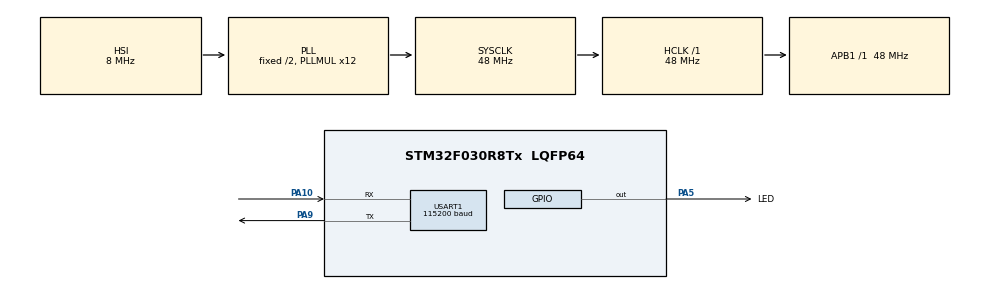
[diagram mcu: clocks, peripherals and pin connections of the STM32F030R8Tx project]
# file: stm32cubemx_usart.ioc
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Mcu.Family=STM32F0
Mcu.Name=STM32F030R8Tx
Mcu.Package=LQFP64
NVIC.USART1_IRQn=true\:0\:0\:false\:false\:true\:true\:true
PA10.GPIO_PuPd=GPIO_NOPULL
PA10.Mode=Asynchronous
PA10.Signal=USART1_RX
PA5.GPIO_Label=LED
PA5.Signal=GPIO_Output
PA9.GPIO_PuPd=GPIO_NOPULL
PA9.Mode=Asynchronous
PA9.Signal=USART1_TX
ProjectManager.HeapSize=0x200
ProjectManager.StackSize=0x400
ProjectManager.TargetToolchain=MDK-ARM V5.27
RCC.AHBFreq_Value=48000000
RCC.APB1Freq_Value=48000000
RCC.APB1TimFreq_Value=48000000
RCC.HCLKFreq_Value=48000000
RCC.PLLMUL=RCC_PLL_MUL12
RCC.SYSCLKFreq_VALUE=48000000
RCC.SYSCLKSource=RCC_SYSCLKSOURCE_PLLCLK
USART1.BaudRate=115200
USART1.VirtualMode-Asynchronous=VM_ASYNC
board=custom

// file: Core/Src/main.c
/* USER CODE BEGIN Header */
/**
  ******************************************************************************
  * @file           : main.c
  * @brief          : Main program body
  ******************************************************************************
  * @attention
  *
  * <h2><center>&copy; Copyright (c) 2020 STMicroelectronics.
  * All rights reserved.</center></h2>
  *
  * This software component is licensed by ST under BSD 3-Clause license,
  * the "License"; You may not use this file except in compliance with the
  * License. You may obtain a copy of the License at:
  *                        opensource.org/licenses/BSD-3-Clause
  *
  ******************************************************************************
  */
/* USER CODE END Header */
#include "main.h"
#include "usart.h"
#include "gpio.h"

/* USER CODE BEGIN Includes */
#include "stdio.h"
/* USER CODE END Includes */

/* USER CODE BEGIN PV */
#define BUFFERSIZE 255           //可以接收的最大字符个数
uint8_t ReceiveBuff[BUFFERSIZE]; //接收缓冲区
uint8_t recv_end_flag = 0,Rx_len;//接收完成中断标志，接收到字符长度

uint8_t RxBuff[1];      //进入中断接收数据的数组
uint8_t DataBuff[5000]; //保存接收到的数据的数组
int RxLine=0;           //接收到的数据长度
/* USER CODE END PV */

void SystemClock_Config(void);
/* USER CODE BEGIN PFP */

//void uart1_data(void);					//接收函数
#ifdef __GNUC__
  #define PUTCHAR_PROTOTYPE int __io_putchar(int ch)
#else
  #define PUTCHAR_PROTOTYPE int fputc(int ch, FILE *f)
#endif

PUTCHAR_PROTOTYPE
{

  // HAL_UART_Transmit_DMA(&huart1, (uint8_t *)&ch,1);
   HAL_UART_Transmit(&huart1, (uint8_t *)(&(ch)), 1, 0xFFFF);
  return ch;
}
/* USER CODE END PFP */

/* USER CODE BEGIN 0 */
//int fputc(int c, FILE *stream)    //重写fputc函数
//{
// /*
//    huart1是工具生成代码定义的UART1结构体，
//    如果以后要使用其他串口打印，只需要把这个结构体改成其他UART结构体。
//*/
//    HAL_UART_Transmit(&huart1, (unsigned char *)&c, 1, 1000);
//    return 1;
//}
//int fputc(int ch, FILE* file)
//{
//    return HAL_UART_Transmit(&huart1, (uint8_t*)&ch, 1, 100);
//}
/* USER CODE END 0 */

int main(void)
{

  /* MCU Configuration--------------------------------------------------------*/

  /* Reset of all peripherals, Initializes the Flash interface and the Systick. */
  HAL_Init();

  /* Configure the system clock */
  SystemClock_Config();

  /* Initialize all configured peripherals */
  MX_GPIO_Init();
  MX_USART1_UART_Init();
  /* USER CODE BEGIN 2 */
	printf("\n111111 \r\n");
//	HAL_UART_Receive_IT(&huart1, (uint8_t *)RxBuff, 1); //打开串口中断接收
//__HAL_UART_ENABLE_IT(&huart1, UART_IT_IDLE);//使能串口1 IDLE中断
  /* USER CODE END 2 */

  /* Infinite loop */
  while (1)
  {

    /* USER CODE BEGIN 3 */

//		printf("\n111111");
		HAL_Delay(1000);
		HAL_GPIO_TogglePin(GPIOA,GPIO_PIN_5);
//		uart1_data();//串口数据处理
  }
  /* USER CODE END 3 */
}

void SystemClock_Config(void)
{
  RCC_OscInitTypeDef RCC_OscInitStruct = {0};
  RCC_ClkInitTypeDef RCC_ClkInitStruct = {0};
  RCC_PeriphCLKInitTypeDef PeriphClkInit = {0};

  /** Initializes the RCC Oscillators according to the specified parameters
  * in the RCC_OscInitTypeDef structure.
  */
  RCC_OscInitStruct.OscillatorType = RCC_OSCILLATORTYPE_HSI;
  RCC_OscInitStruct.HSIState = RCC_HSI_ON;
  RCC_OscInitStruct.HSICalibrationValue = RCC_HSICALIBRATION_DEFAULT;
  RCC_OscInitStruct.PLL.PLLState = RCC_PLL_ON;
  RCC_OscInitStruct.PLL.PLLSource = RCC_PLLSOURCE_HSI;
  RCC_OscInitStruct.PLL.PLLMUL = RCC_PLL_MUL12;
  RCC_OscInitStruct.PLL.PREDIV = RCC_PREDIV_DIV1;
  if (HAL_RCC_OscConfig(&RCC_OscInitStruct) != HAL_OK)
  {
    Error_Handler();
  }
  /** Initializes the CPU, AHB and APB buses clocks
  */
  RCC_ClkInitStruct.ClockType = RCC_CLOCKTYPE_HCLK|RCC_CLOCKTYPE_SYSCLK
                              |RCC_CLOCKTYPE_PCLK1;
  RCC_ClkInitStruct.SYSCLKSource = RCC_SYSCLKSOURCE_PLLCLK;
  RCC_ClkInitStruct.AHBCLKDivider = RCC_SYSCLK_DIV1;
  RCC_ClkInitStruct.APB1CLKDivider = RCC_HCLK_DIV1;

  if (HAL_RCC_ClockConfig(&RCC_ClkInitStruct, FLASH_LATENCY_1) != HAL_OK)
  {
    Error_Handler();
  }
  PeriphClkInit.PeriphClockSelection = RCC_PERIPHCLK_USART1;
  PeriphClkInit.Usart1ClockSelection = RCC_USART1CLKSOURCE_PCLK1;
  if (HAL_RCCEx_PeriphCLKConfig(&PeriphClkInit) != HAL_OK)
  {
    Error_Handler();
  }
}

/* USER CODE BEGIN 4 */
//void uart1_data(void)
//{
//	if(recv_end_flag ==1)//接收完成标志
//	{
//		printf("数据长度=%d\r\n",Rx_len);//打印接收到的数据长度
//		printf("数据内容:");
//		for(int i=0;i<Rx_len;i++)
//		{
//			printf("%c",ReceiveBuff[i]);//向串口打印接收到的数据
//            }
//    printf("\r\n");
//    for(int i = 0; i < Rx_len ; i++) //清空接收缓存区
//    ReceiveBuff[i]=0;//置0
//    Rx_len=0;//接收数据长度清零
//    recv_end_flag=0;//接收标志位清零
//    }
//    //开启下一次接收
//    HAL_UART_Receive_DMA(&huart1,(uint8_t*)ReceiveBuff,BUFFERSIZE);
//}
/* USER CODE END 4 */

void Error_Handler(void)
{
}

/************************ (C) COPYRIGHT STMicroelectronics *****END OF FILE****/
